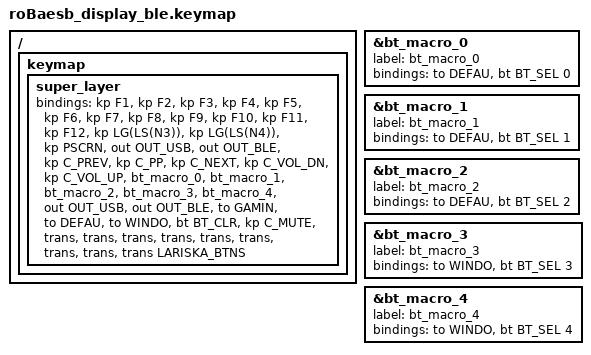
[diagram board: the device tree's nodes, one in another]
#include "roBaesb.keymap"
#include <dt-bindings/zmk/bt.h>

&bt_macro_0 {
    label = "bt_macro_0";
    bindings = <&to DEFAU>, <&bt BT_SEL 0>;
};

&bt_macro_1 {
    label = "bt_macro_1";
    bindings = <&to DEFAU>, <&bt BT_SEL 1>;
};

&bt_macro_2 {
    label = "bt_macro_2";
    bindings = <&to DEFAU>, <&bt BT_SEL 2>;
};

&bt_macro_3 {
    label = "bt_macro_3";
    bindings = <&to WINDO>, <&bt BT_SEL 3>;
};

&bt_macro_4 {
    label = "bt_macro_4";
    bindings = <&to WINDO>, <&bt BT_SEL 4>;
};

/ {
    keymap {
        super_layer {
            bindings = <
 &kp F1                &kp F2                &kp F3                &kp F4                &kp F5                &kp F6                &kp F7                &kp F8                &kp F9               &kp F10
 &kp F11               &kp F12              &kp LG(LS(N3))       &kp LG(LS(N4))       &kp PSCRN            &out OUT_USB         &out OUT_BLE         &kp C_PREV            &kp C_PP              &kp C_NEXT           &kp C_VOL_DN         &kp C_VOL_UP
 &bt_macro_0           &bt_macro_1           &bt_macro_2           &bt_macro_3           &bt_macro_4           &out OUT_USB         &out OUT_BLE         &to GAMIN            &to DEFAU            &to WINDO            &bt BT_CLR           &kp C_MUTE
 &trans               &trans               &trans               &trans               &trans               &trans               &trans               &trans               &trans
 LARISKA_BTNS
            >;
        };
    };
};
